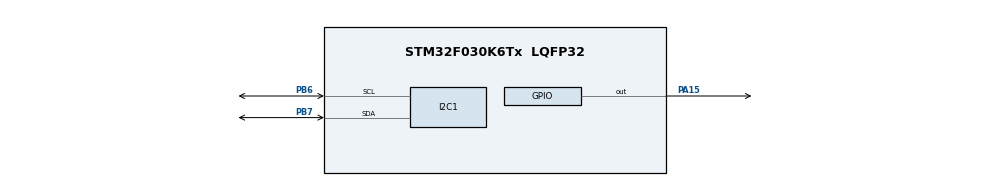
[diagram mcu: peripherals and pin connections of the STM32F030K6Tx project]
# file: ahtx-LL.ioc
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Mcu.Family=STM32F0
Mcu.Name=STM32F030K6Tx
Mcu.Package=LQFP32
PA13.Mode=Serial_Wire
PA13.Signal=SYS_SWDIO
PA14.Mode=Serial_Wire
PA14.Signal=SYS_SWCLK
PA15.Signal=GPIO_Output
PB6.Mode=I2C
PB6.Signal=I2C1_SCL
PB7.Mode=I2C
PB7.Signal=I2C1_SDA
PF0-OSC_IN.Mode=HSE-External-Oscillator
PF0-OSC_IN.Signal=RCC_OSC_IN
PF1-OSC_OUT.Mode=HSE-External-Oscillator
PF1-OSC_OUT.Signal=RCC_OSC_OUT
ProjectManager.HeapSize=0x200
ProjectManager.StackSize=0x400
ProjectManager.TargetToolchain=STM32CubeIDE
RCC.AHBFreq_Value=48000000
RCC.APB1Freq_Value=48000000
RCC.APB1TimFreq_Value=48000000
RCC.EnbaleCSS=true
RCC.HCLKFreq_Value=48000000
RCC.PLLMUL=RCC_PLL_MUL6
RCC.PLLSourceVirtual=RCC_PLLSOURCE_HSE
RCC.SYSCLKFreq_VALUE=48000000
RCC.SYSCLKSource=RCC_SYSCLKSOURCE_PLLCLK
board=custom

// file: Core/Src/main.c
/* USER CODE BEGIN Header */
/**
  ******************************************************************************
  * @file           : main.c
  * @brief          : Main program body
  ******************************************************************************
  * @attention
  *
  * Copyright (c) 2023 STMicroelectronics.
  * All rights reserved.
  *
  * This software is licensed under terms that can be found in the LICENSE file
  * in the root directory of this software component.
  * If no LICENSE file comes with this software, it is provided AS-IS.
  *
  ******************************************************************************
  */
/* USER CODE END Header */
#include "main.h"

/* USER CODE BEGIN PD */
#define AHT20_I2C_ADDRESS 0x38 << 1
#define AHT20_INIT_CMD 0xBE
#define AHT20_START_MEASUREMENT_CMD 0xAC
#define AHT20_SOFT_RESET_CMD 0xBA
/* USER CODE END PD */

/* USER CODE BEGIN PV */
uint8_t data[6];
float temperature, humidity;
/* USER CODE END PV */

void SystemClock_Config(void);
static void MX_GPIO_Init(void);
static void MX_I2C1_Init(void);
/* USER CODE BEGIN PFP */
void AHT20_Init(void);
void AHT20_StartMeasurement(void);
void AHT20_ReadData(uint8_t *data);
float AHT20_GetTemperature(uint8_t *data);
float AHT20_GetHumidity(uint8_t *data);
/* USER CODE END PFP */

/* USER CODE BEGIN 0 */
void AHT20_Init(void)
{
    uint8_t init_cmd[] = {AHT20_INIT_CMD, 0x08, 0x00};
    uint8_t cmd_length = sizeof(init_cmd) / sizeof(init_cmd[0]);

    LL_I2C_HandleTransfer(I2C1, AHT20_I2C_ADDRESS, LL_I2C_ADDRSLAVE_7BIT, cmd_length, LL_I2C_MODE_AUTOEND, LL_I2C_GENERATE_START_WRITE);
    for (uint8_t i = 0; i < cmd_length; i++)
    {
        while (!LL_I2C_IsActiveFlag_TXIS(I2C1))
        {
        }
        LL_I2C_TransmitData8(I2C1, init_cmd[i]);
    }
    while (!LL_I2C_IsActiveFlag_STOP(I2C1))
    {
    }
    LL_I2C_ClearFlag_STOP(I2C1);
}

void AHT20_StartMeasurement(void)
{
 uint8_t start_measurement_cmd[] = {AHT20_START_MEASUREMENT_CMD, 0x33, 0x00};
    uint8_t cmd_length = sizeof(start_measurement_cmd) / sizeof(start_measurement_cmd[0]);

    LL_I2C_HandleTransfer(I2C1, AHT20_I2C_ADDRESS, LL_I2C_ADDRSLAVE_7BIT, cmd_length, LL_I2C_MODE_AUTOEND, LL_I2C_GENERATE_START_WRITE);
    for (uint8_t i = 0; i < cmd_length; i++)
    {
        while (!LL_I2C_IsActiveFlag_TXIS(I2C1))
        {
        }
        LL_I2C_TransmitData8(I2C1, start_measurement_cmd[i]);
    }
    while (!LL_I2C_IsActiveFlag_STOP(I2C1))
    {
    }
    LL_I2C_ClearFlag_STOP(I2C1);
}

void AHT20_ReadData(uint8_t *data)
{
    LL_I2C_HandleTransfer(I2C1, AHT20_I2C_ADDRESS, LL_I2C_ADDRSLAVE_7BIT, 6, LL_I2C_MODE_AUTOEND, LL_I2C_GENERATE_START_READ);
    while (!LL_I2C_IsActiveFlag_STOP(I2C1))
    {
        if (LL_I2C_IsActiveFlag_RXNE(I2C1))
        {
            *data++ = LL_I2C_ReceiveData8(I2C1);
        }
    }
    LL_I2C_ClearFlag_STOP(I2C1);
}

float AHT20_GetTemperature(uint8_t *data)
{
    uint32_t raw_temperature = ((uint32_t)(data[3] & 0x0F) << 16) | ((uint32_t)data[4] << 8) | data[5];
    return ((float)raw_temperature * 200.0 / 1048576.0) - 50.0;
}

float AHT20_GetHumidity(uint8_t *data)
{
    uint32_t raw_humidity = ((uint32_t)data[1] << 12) | ((uint32_t)data[2] << 4) | (data[3] >> 4);
    return (float)raw_humidity * 100.0 / 1048576.0;
}
/* USER CODE END 0 */

int main(void)
{

  /* MCU Configuration--------------------------------------------------------*/

  /* Reset of all peripherals, Initializes the Flash interface and the Systick. */
  LL_APB1_GRP2_EnableClock(LL_APB1_GRP2_PERIPH_SYSCFG);
  LL_APB1_GRP1_EnableClock(LL_APB1_GRP1_PERIPH_PWR);

  /* SysTick_IRQn interrupt configuration */
  NVIC_SetPriority(SysTick_IRQn, 3);

  /* Configure the system clock */
  SystemClock_Config();

  /* Initialize all configured peripherals */
  MX_GPIO_Init();
  MX_I2C1_Init();
  /* USER CODE BEGIN 2 */
  AHT20_Init();

  /* USER CODE END 2 */

  /* Infinite loop */
  /* USER CODE BEGIN WHILE */
  while (1)
  {
	  AHT20_StartMeasurement();
	  LL_mDelay(100); // Wait for the measurement to complete
	  AHT20_ReadData(data);
      temperature = AHT20_GetTemperature(data);
	  humidity = AHT20_GetHumidity(data);
	  LL_GPIO_SetOutputPin(GPIOA, LL_GPIO_PIN_15);
	  LL_mDelay(100);
	  LL_GPIO_ResetOutputPin(GPIOA, LL_GPIO_PIN_15);

    /* USER CODE END WHILE */

  }
}

void SystemClock_Config(void)
{
  LL_FLASH_SetLatency(LL_FLASH_LATENCY_1);
  while(LL_FLASH_GetLatency() != LL_FLASH_LATENCY_1)
  {
  }
  LL_RCC_HSE_Enable();

   /* Wait till HSE is ready */
  while(LL_RCC_HSE_IsReady() != 1)
  {

  }
  LL_RCC_HSI_Enable();

   /* Wait till HSI is ready */
  while(LL_RCC_HSI_IsReady() != 1)
  {

  }
  LL_RCC_HSI_SetCalibTrimming(16);
  LL_RCC_HSE_EnableCSS();
  LL_RCC_PLL_ConfigDomain_SYS(LL_RCC_PLLSOURCE_HSE_DIV_1, LL_RCC_PLL_MUL_6);
  LL_RCC_PLL_Enable();

   /* Wait till PLL is ready */
  while(LL_RCC_PLL_IsReady() != 1)
  {

  }
  LL_RCC_SetAHBPrescaler(LL_RCC_SYSCLK_DIV_1);
  LL_RCC_SetAPB1Prescaler(LL_RCC_APB1_DIV_1);
  LL_RCC_SetSysClkSource(LL_RCC_SYS_CLKSOURCE_PLL);

   /* Wait till System clock is ready */
  while(LL_RCC_GetSysClkSource() != LL_RCC_SYS_CLKSOURCE_STATUS_PLL)
  {

  }
  LL_Init1msTick(48000000);
  LL_SetSystemCoreClock(48000000);
  LL_RCC_SetI2CClockSource(LL_RCC_I2C1_CLKSOURCE_HSI);
}

static void MX_I2C1_Init(void)
{

  LL_I2C_InitTypeDef I2C_InitStruct = {0};

  LL_GPIO_InitTypeDef GPIO_InitStruct = {0};

  LL_AHB1_GRP1_EnableClock(LL_AHB1_GRP1_PERIPH_GPIOB);
  /**I2C1 GPIO Configuration
  PB6   ------> I2C1_SCL
  PB7   ------> I2C1_SDA
  */
  GPIO_InitStruct.Pin = LL_GPIO_PIN_6;
  GPIO_InitStruct.Mode = LL_GPIO_MODE_ALTERNATE;
  GPIO_InitStruct.Speed = LL_GPIO_SPEED_FREQ_HIGH;
  GPIO_InitStruct.OutputType = LL_GPIO_OUTPUT_OPENDRAIN;
  GPIO_InitStruct.Pull = LL_GPIO_PULL_NO;
  GPIO_InitStruct.Alternate = LL_GPIO_AF_1;
  LL_GPIO_Init(GPIOB, &GPIO_InitStruct);

  GPIO_InitStruct.Pin = LL_GPIO_PIN_7;
  GPIO_InitStruct.Mode = LL_GPIO_MODE_ALTERNATE;
  GPIO_InitStruct.Speed = LL_GPIO_SPEED_FREQ_HIGH;
  GPIO_InitStruct.OutputType = LL_GPIO_OUTPUT_OPENDRAIN;
  GPIO_InitStruct.Pull = LL_GPIO_PULL_NO;
  GPIO_InitStruct.Alternate = LL_GPIO_AF_1;
  LL_GPIO_Init(GPIOB, &GPIO_InitStruct);

  /* Peripheral clock enable */
  LL_APB1_GRP1_EnableClock(LL_APB1_GRP1_PERIPH_I2C1);

  /** I2C Initialization
  */
  LL_I2C_DisableOwnAddress2(I2C1);
  LL_I2C_DisableGeneralCall(I2C1);
  LL_I2C_EnableClockStretching(I2C1);
  I2C_InitStruct.PeripheralMode = LL_I2C_MODE_I2C;
  I2C_InitStruct.Timing = 0x2000090E;
  I2C_InitStruct.AnalogFilter = LL_I2C_ANALOGFILTER_ENABLE;
  I2C_InitStruct.DigitalFilter = 0;
  I2C_InitStruct.OwnAddress1 = 0;
  I2C_InitStruct.TypeAcknowledge = LL_I2C_ACK;
  I2C_InitStruct.OwnAddrSize = LL_I2C_OWNADDRESS1_7BIT;
  LL_I2C_Init(I2C1, &I2C_InitStruct);
  LL_I2C_EnableAutoEndMode(I2C1);
  LL_I2C_SetOwnAddress2(I2C1, 0, LL_I2C_OWNADDRESS2_NOMASK);

}

static void MX_GPIO_Init(void)
{
  LL_GPIO_InitTypeDef GPIO_InitStruct = {0};

  /* GPIO Ports Clock Enable */
  LL_AHB1_GRP1_EnableClock(LL_AHB1_GRP1_PERIPH_GPIOF);
  LL_AHB1_GRP1_EnableClock(LL_AHB1_GRP1_PERIPH_GPIOA);
  LL_AHB1_GRP1_EnableClock(LL_AHB1_GRP1_PERIPH_GPIOB);

  /**/
  LL_GPIO_ResetOutputPin(GPIOA, LL_GPIO_PIN_15);

  /**/
  GPIO_InitStruct.Pin = LL_GPIO_PIN_15;
  GPIO_InitStruct.Mode = LL_GPIO_MODE_OUTPUT;
  GPIO_InitStruct.Speed = LL_GPIO_SPEED_FREQ_LOW;
  GPIO_InitStruct.OutputType = LL_GPIO_OUTPUT_PUSHPULL;
  GPIO_InitStruct.Pull = LL_GPIO_PULL_NO;
  LL_GPIO_Init(GPIOA, &GPIO_InitStruct);

}

void Error_Handler(void)
{
  __disable_irq();
  while (1)
  {
  }
}
